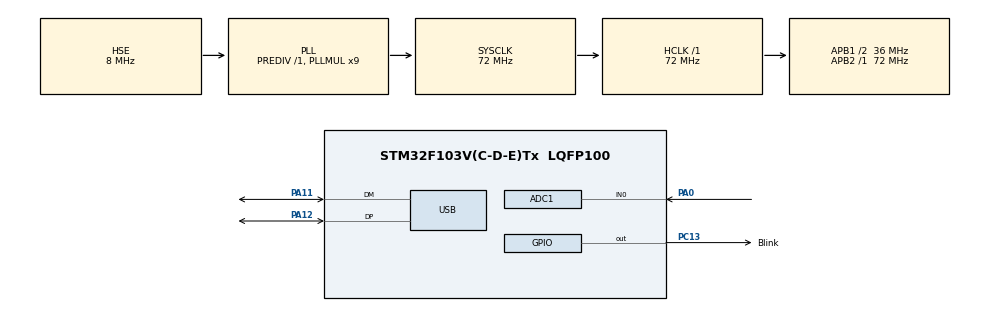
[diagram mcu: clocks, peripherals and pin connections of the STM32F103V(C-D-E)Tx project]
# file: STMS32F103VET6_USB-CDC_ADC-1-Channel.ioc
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ADC1.Channel-0\#ChannelRegularConversion=ADC_CHANNEL_0
ADC1.ContinuousConvMode=DISABLE
ADC1.DataAlign=ADC_DATAALIGN_RIGHT
ADC1.DiscontinuousConvMode=DISABLE
ADC1.EnableAnalogWatchDog=false
ADC1.EnableRegularConversion=ENABLE
ADC1.ExternalTrigConv=ADC_SOFTWARE_START
ADC1.InjNumberOfConversion=0
ADC1.NbrOfConversion=1
ADC1.NbrOfConversionFlag=1
ADC1.Rank-0\#ChannelRegularConversion=1
ADC1.SamplingTime-0\#ChannelRegularConversion=ADC_SAMPLETIME_239CYCLES_5
ADC1.ScanConvMode=ADC_SCAN_DISABLE
ADC1.master=1
Dma.ADC1.0.Direction=DMA_PERIPH_TO_MEMORY
Dma.ADC1.0.Instance=DMA1_Channel1
Dma.ADC1.0.MemDataAlignment=DMA_MDATAALIGN_HALFWORD
Dma.ADC1.0.MemInc=DMA_MINC_ENABLE
Dma.ADC1.0.Mode=DMA_CIRCULAR
Dma.ADC1.0.PeriphDataAlignment=DMA_PDATAALIGN_HALFWORD
Dma.ADC1.0.PeriphInc=DMA_PINC_DISABLE
Dma.ADC1.0.Priority=DMA_PRIORITY_LOW
Dma.Request0=ADC1
Mcu.Family=STM32F1
Mcu.Name=STM32F103V(C-D-E)Tx
Mcu.Package=LQFP100
NVIC.DMA1_Channel1_IRQn=true\:0\:0\:false\:false\:true
NVIC.PriorityGroup=NVIC_PRIORITYGROUP_4
NVIC.USB_LP_CAN1_RX0_IRQn=true\:0\:0\:false\:false\:true
OSC_IN.Mode=HSE-External-Oscillator
OSC_IN.Signal=RCC_OSC_IN
OSC_OUT.Mode=HSE-External-Oscillator
OSC_OUT.Signal=RCC_OSC_OUT
PA0-WKUP.Signal=ADCx_IN0
PA11.Mode=Device
PA11.Signal=USB_DM
PA12.Mode=Device
PA12.Signal=USB_DP
PA13.Mode=Serial_Wire
PA13.Signal=SYS_JTMS-SWDIO
PA14.Mode=Serial_Wire
PA14.Signal=SYS_JTCK-SWCLK
PC13-TAMPER-RTC.GPIO_Label=Blink
PC13-TAMPER-RTC.Signal=GPIO_Output
ProjectManager.HeapSize=0x200
ProjectManager.StackSize=0x400
ProjectManager.TargetToolchain=MDK-ARM V5
RCC.ADCPresc=RCC_ADCPCLK2_DIV6
RCC.AHBFreq_Value=72000000
RCC.APB1CLKDivider=RCC_HCLK_DIV2
RCC.APB1Freq_Value=36000000
RCC.APB1TimFreq_Value=72000000
RCC.APB2Freq_Value=72000000
RCC.APB2TimFreq_Value=72000000
RCC.HCLKFreq_Value=72000000
RCC.HSIState=RCC_HSI_ON
RCC.PLLMUL=RCC_PLL_MUL9
RCC.SYSCLKFreq_VALUE=72000000
RCC.SYSCLKSource=RCC_SYSCLKSOURCE_PLLCLK
RCC.USBFreq_Value=48000000
RCC.USBPrescaler=RCC_USBCLKSOURCE_PLL_DIV1_5
SH.ADCx_IN0.0=ADC1_IN0,IN0
USB.ep0_mps=DEP0CTL_MPS_64
USB_DEVICE.CLASS_NAME_FS=CDC
USB_DEVICE.MANUFACTURER_STRING=Electronic4U
USB_DEVICE.USBD_HandleTypeDef=hUsbDeviceFS
USB_DEVICE.VirtualMode=Cdc
USB_DEVICE.VirtualModeFS=Cdc_FS
VP_USB_DEVICE_VS_USB_DEVICE_CDC_FS.Mode=CDC_FS
board=STMS32F103VET6_USB-CDC_ADC-1-Channel

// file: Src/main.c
/**
  ******************************************************************************
  * File Name          : main.c
  * Description        : Main program body
  ******************************************************************************
  *
  * Copyright (c) 2016 STMicroelectronics International N.V.
  * All rights reserved.
  *
  * Redistribution and use in source and binary forms, with or without
  * modification, are permitted, provided that the following conditions are met:
  *
  * 1. Redistribution of source code must retain the above copyright notice,
  *    this list of conditions and the following disclaimer.
  * 2. Redistributions in binary form must reproduce the above copyright notice,
  *    this list of conditions and the following disclaimer in the documentation
  *    and/or other materials provided with the distribution.
  * 3. Neither the name of STMicroelectronics nor the names of other
  *    contributors to this software may be used to endorse or promote products
  *    derived from this software without specific written permission.
  * 4. This software, including modifications and/or derivative works of this
  *    software, must execute solely and exclusively on microcontroller or
  *    microprocessor devices manufactured by or for STMicroelectronics.
  * 5. Redistribution and use of this software other than as permitted under
  *    this license is void and will automatically terminate your rights under
  *    this license.
  *
  * THIS SOFTWARE IS PROVIDED BY STMICROELECTRONICS AND CONTRIBUTORS "AS IS"
  * AND ANY EXPRESS, IMPLIED OR STATUTORY WARRANTIES, INCLUDING, BUT NOT
  * LIMITED TO, THE IMPLIED WARRANTIES OF MERCHANTABILITY, FITNESS FOR A
  * PARTICULAR PURPOSE AND NON-INFRINGEMENT OF THIRD PARTY INTELLECTUAL PROPERTY
  * RIGHTS ARE DISCLAIMED TO THE FULLEST EXTENT PERMITTED BY LAW. IN NO EVENT
  * SHALL STMICROELECTRONICS OR CONTRIBUTORS BE LIABLE FOR ANY DIRECT, INDIRECT,
  * INCIDENTAL, SPECIAL, EXEMPLARY, OR CONSEQUENTIAL DAMAGES (INCLUDING, BUT NOT
  * LIMITED TO, PROCUREMENT OF SUBSTITUTE GOODS OR SERVICES; LOSS OF USE, DATA,
  * OR PROFITS; OR BUSINESS INTERRUPTION) HOWEVER CAUSED AND ON ANY THEORY OF
  * LIABILITY, WHETHER IN CONTRACT, STRICT LIABILITY, OR TORT (INCLUDING
  * NEGLIGENCE OR OTHERWISE) ARISING IN ANY WAY OUT OF THE USE OF THIS SOFTWARE,
  * EVEN IF ADVISED OF THE POSSIBILITY OF SUCH DAMAGE.
  *
  ******************************************************************************
  */
#include "main.h"
#include "stm32f1xx_hal.h"
#include "usb_device.h"

/* USER CODE BEGIN Includes */
#include "usbd_cdc_if.h"
/* USER CODE END Includes */

ADC_HandleTypeDef hadc1;
DMA_HandleTypeDef hdma_adc1;

/* USER CODE BEGIN PV */
/* Private variables ---------------------------------------------------------*/

/* USER CODE END PV */

void SystemClock_Config(void);
void Error_Handler(void);
static void MX_GPIO_Init(void);
static void MX_DMA_Init(void);
static void MX_ADC1_Init(void);

/* USER CODE BEGIN PFP */
/* Private function prototypes -----------------------------------------------*/

/* USER CODE END PFP */

/* USER CODE BEGIN 0 */
unsigned char ADC_Data[5];
uint16_t ADC_Value;

uint8_t RX_Data[64];
uint8_t RX_Size;
uint8_t mystring[]="Electronic4U Wellcom \r";
/* USER CODE END 0 */

int main(void)
{

  /* MCU Configuration----------------------------------------------------------*/

  /* Reset of all peripherals, Initializes the Flash interface and the Systick. */
  HAL_Init();

  /* Configure the system clock */
  SystemClock_Config();

  /* Initialize all configured peripherals */
  MX_GPIO_Init();
  MX_DMA_Init();
  MX_ADC1_Init();
  MX_USB_DEVICE_Init();

  /* Infinite loop */
  while (1)
  {

  /* USER CODE BEGIN 3 */
		HAL_ADC_Start_DMA(&hadc1,(uint32_t*)&ADC_Value,1);					// Bat dau thuc hien doc 1 ADC vao bien ADC_Value
		HAL_Delay(1);
		HAL_ADC_Stop_DMA(&hadc1);																		// Ket thuc qua trinh doc ADC
		sprintf((char *)ADC_Data,"%5d",ADC_Value);									// Chuyen doi "ADC_Value - kieu uint16_t" sang "ADC_Data - kieu Char"
		CDC_Transmit_FS(ADC_Data, strlen((const char*)ADC_Data));		// Gui "ADC_Data - kieu Char" da nhan duoc qua cong USB

		HAL_GPIO_TogglePin(GPIOC, GPIO_PIN_13);
		HAL_Delay(500);
  }
  /* USER CODE END 3 */

}

/** System Clock Configuration
*/
void SystemClock_Config(void)
{

  RCC_OscInitTypeDef RCC_OscInitStruct;
  RCC_ClkInitTypeDef RCC_ClkInitStruct;
  RCC_PeriphCLKInitTypeDef PeriphClkInit;

    /**Initializes the CPU, AHB and APB busses clocks
    */
  RCC_OscInitStruct.OscillatorType = RCC_OSCILLATORTYPE_HSE;
  RCC_OscInitStruct.HSEState = RCC_HSE_ON;
  RCC_OscInitStruct.HSEPredivValue = RCC_HSE_PREDIV_DIV1;
  RCC_OscInitStruct.HSIState = RCC_HSI_ON;
  RCC_OscInitStruct.PLL.PLLState = RCC_PLL_ON;
  RCC_OscInitStruct.PLL.PLLSource = RCC_PLLSOURCE_HSE;
  RCC_OscInitStruct.PLL.PLLMUL = RCC_PLL_MUL9;
  if (HAL_RCC_OscConfig(&RCC_OscInitStruct) != HAL_OK)
  {
    Error_Handler();
  }

    /**Initializes the CPU, AHB and APB busses clocks
    */
  RCC_ClkInitStruct.ClockType = RCC_CLOCKTYPE_HCLK|RCC_CLOCKTYPE_SYSCLK
                              |RCC_CLOCKTYPE_PCLK1|RCC_CLOCKTYPE_PCLK2;
  RCC_ClkInitStruct.SYSCLKSource = RCC_SYSCLKSOURCE_PLLCLK;
  RCC_ClkInitStruct.AHBCLKDivider = RCC_SYSCLK_DIV1;
  RCC_ClkInitStruct.APB1CLKDivider = RCC_HCLK_DIV2;
  RCC_ClkInitStruct.APB2CLKDivider = RCC_HCLK_DIV1;

  if (HAL_RCC_ClockConfig(&RCC_ClkInitStruct, FLASH_LATENCY_2) != HAL_OK)
  {
    Error_Handler();
  }

  PeriphClkInit.PeriphClockSelection = RCC_PERIPHCLK_ADC|RCC_PERIPHCLK_USB;
  PeriphClkInit.AdcClockSelection = RCC_ADCPCLK2_DIV6;
  PeriphClkInit.UsbClockSelection = RCC_USBCLKSOURCE_PLL_DIV1_5;
  if (HAL_RCCEx_PeriphCLKConfig(&PeriphClkInit) != HAL_OK)
  {
    Error_Handler();
  }

    /**Configure the Systick interrupt time
    */
  HAL_SYSTICK_Config(HAL_RCC_GetHCLKFreq()/1000);

    /**Configure the Systick
    */
  HAL_SYSTICK_CLKSourceConfig(SYSTICK_CLKSOURCE_HCLK);

  /* SysTick_IRQn interrupt configuration */
  HAL_NVIC_SetPriority(SysTick_IRQn, 0, 0);
}

/* ADC1 init function */
static void MX_ADC1_Init(void)
{

  ADC_ChannelConfTypeDef sConfig;

    /**Common config
    */
  hadc1.Instance = ADC1;
  hadc1.Init.ScanConvMode = ADC_SCAN_DISABLE;
  hadc1.Init.ContinuousConvMode = DISABLE;
  hadc1.Init.DiscontinuousConvMode = DISABLE;
  hadc1.Init.ExternalTrigConv = ADC_SOFTWARE_START;
  hadc1.Init.DataAlign = ADC_DATAALIGN_RIGHT;
  hadc1.Init.NbrOfConversion = 1;
  if (HAL_ADC_Init(&hadc1) != HAL_OK)
  {
    Error_Handler();
  }

    /**Configure Regular Channel
    */
  sConfig.Channel = ADC_CHANNEL_0;
  sConfig.Rank = 1;
  sConfig.SamplingTime = ADC_SAMPLETIME_239CYCLES_5;
  if (HAL_ADC_ConfigChannel(&hadc1, &sConfig) != HAL_OK)
  {
    Error_Handler();
  }

}

static void MX_DMA_Init(void)
{
  /* DMA controller clock enable */
  __HAL_RCC_DMA1_CLK_ENABLE();

  /* DMA interrupt init */
  /* DMA1_Channel1_IRQn interrupt configuration */
  HAL_NVIC_SetPriority(DMA1_Channel1_IRQn, 0, 0);
  HAL_NVIC_EnableIRQ(DMA1_Channel1_IRQn);

}

/** Configure pins as
        * Analog
        * Input
        * Output
        * EVENT_OUT
        * EXTI
*/
static void MX_GPIO_Init(void)
{

  GPIO_InitTypeDef GPIO_InitStruct;

  /* GPIO Ports Clock Enable */
  __HAL_RCC_GPIOC_CLK_ENABLE();
  __HAL_RCC_GPIOA_CLK_ENABLE();

  /*Configure GPIO pin Output Level */
  HAL_GPIO_WritePin(Blink_GPIO_Port, Blink_Pin, GPIO_PIN_RESET);

  /*Configure GPIO pin : Blink_Pin */
  GPIO_InitStruct.Pin = Blink_Pin;
  GPIO_InitStruct.Mode = GPIO_MODE_OUTPUT_PP;
  GPIO_InitStruct.Speed = GPIO_SPEED_FREQ_LOW;
  HAL_GPIO_Init(Blink_GPIO_Port, &GPIO_InitStruct);

}

void Error_Handler(void)
{
  while(1)
  {
  }
}

/************************ (C) COPYRIGHT STMicroelectronics *****END OF FILE****/
